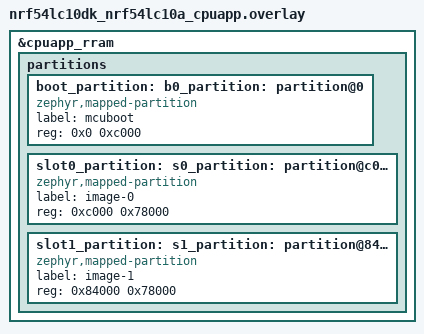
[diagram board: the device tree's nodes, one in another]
/*
 * Copyright (c) 2026 Nordic Semiconductor ASA
 *
 * SPDX-License-Identifier: LicenseRef-Nordic-5-Clause
 */

/delete-node/ &boot_partition;
/delete-node/ &slot0_partition;
/delete-node/ &slot1_partition;
/delete-node/ &storage_partition;

&cpuapp_rram {
	partitions {
		boot_partition: partition@0 {
			compatible = "zephyr,mapped-partition";
			label = "mcuboot";
			reg = <0x0 0xc000>;
		};

		slot0_partition: partition@c000 {
			compatible = "zephyr,mapped-partition";
			label = "image-0";
			reg = <0xc000 0x78000>;
		};

		slot1_partition: partition@84000 {
			compatible = "zephyr,mapped-partition";
			label = "image-1";
			reg = <0x84000 0x78000>;
		};

		/* EMPTY_0: 0xfc000 to 0xfd000 (4 kB) */
	};
};

b0_partition: &boot_partition {};

s0_partition: &slot0_partition {};

s1_partition: &slot1_partition {};
